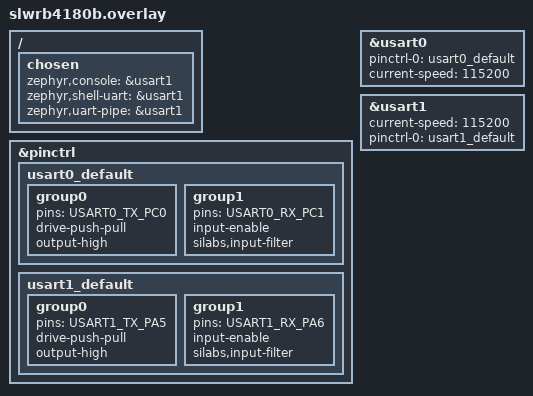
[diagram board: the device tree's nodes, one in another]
/*
 * Copyright (c) 2025, Silicon Laboratories Inc.
 *
 * SPDX-License-Identifier: Apache-2.0
 */

/*
 * Connect EXP4 (PC0) and EXP6 (PC1) of the Expansion Pin header
 */
/ {
	chosen {
		zephyr,console = &usart1;
		zephyr,shell-uart = &usart1;
		zephyr,uart-pipe = &usart1;
	};
};

&pinctrl {
	usart0_default: usart0_default {
		group0 {
			pins = <USART0_TX_PC0>; /* EXP4 (PC0) */
			drive-push-pull;
			output-high;
		};

		group1 {
			pins = <USART0_RX_PC1>; /* EXP6 (PC1) */
			input-enable;
			silabs,input-filter;
		};
	};

	usart1_default: usart1_default {
		group0 {
			pins = <USART1_TX_PA5>;
			drive-push-pull;
			output-high;
		};

		group1 {
			pins = <USART1_RX_PA6>;
			input-enable;
			silabs,input-filter;
		};
	};
};

dut: &usart0 {
	pinctrl-0 = <&usart0_default>;
	pinctrl-names = "default";
	current-speed = <115200>;
	status = "okay";
};

&usart1 {
	current-speed = <115200>;
	pinctrl-0 = <&usart1_default>;
	pinctrl-names = "default";
	status = "okay";
};
